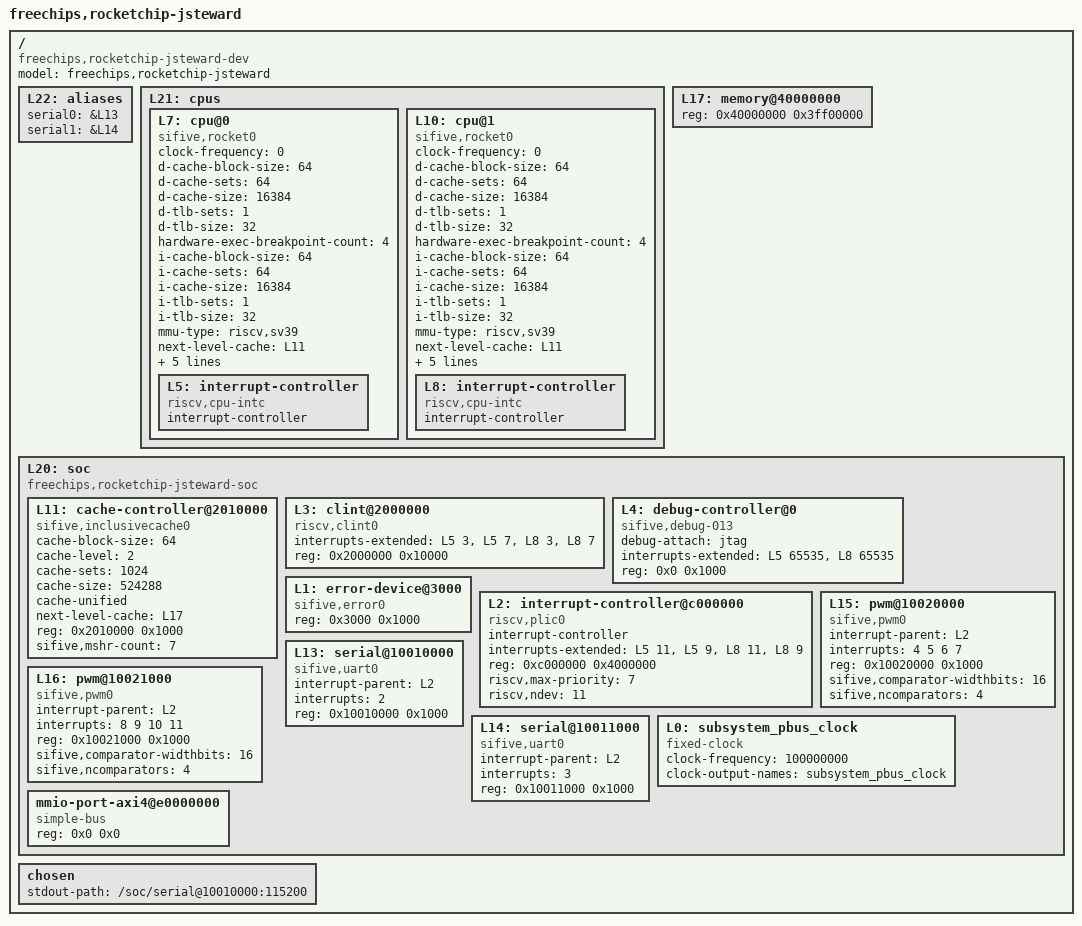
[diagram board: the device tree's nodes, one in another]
/dts-v1/;

/ {
	#address-cells = <1>;
	#size-cells = <1>;
	compatible = "freechips,rocketchip-jsteward-dev";
	model = "freechips,rocketchip-jsteward";
	L22: aliases {
		serial0 = &L13;
		serial1 = &L14;
	};
	L21: cpus {
		#address-cells = <1>;
		#size-cells = <0>;
		L7: cpu@0 {
			clock-frequency = <0>;
			compatible = "sifive,rocket0", "riscv";
			d-cache-block-size = <64>;
			d-cache-sets = <64>;
			d-cache-size = <16384>;
			d-tlb-sets = <1>;
			d-tlb-size = <32>;
			device_type = "cpu";
			hardware-exec-breakpoint-count = <4>;
			i-cache-block-size = <64>;
			i-cache-sets = <64>;
			i-cache-size = <16384>;
			i-tlb-sets = <1>;
			i-tlb-size = <32>;
			mmu-type = "riscv,sv39";
			next-level-cache = <&L11>;
			reg = <0x0>;
			riscv,isa = "rv64imafdc";
			riscv,pmpregions = <8>;
			status = "okay";
			timebase-frequency = <100000000>;
			tlb-split;
			L5: interrupt-controller {
				#interrupt-cells = <1>;
				compatible = "riscv,cpu-intc";
				interrupt-controller;
			};
		};
		L10: cpu@1 {
			clock-frequency = <0>;
			compatible = "sifive,rocket0", "riscv";
			d-cache-block-size = <64>;
			d-cache-sets = <64>;
			d-cache-size = <16384>;
			d-tlb-sets = <1>;
			d-tlb-size = <32>;
			device_type = "cpu";
			hardware-exec-breakpoint-count = <4>;
			i-cache-block-size = <64>;
			i-cache-sets = <64>;
			i-cache-size = <16384>;
			i-tlb-sets = <1>;
			i-tlb-size = <32>;
			mmu-type = "riscv,sv39";
			next-level-cache = <&L11>;
			reg = <0x1>;
			riscv,isa = "rv64imafdc";
			riscv,pmpregions = <8>;
			status = "okay";
			timebase-frequency = <100000000>;
			tlb-split;
			L8: interrupt-controller {
				#interrupt-cells = <1>;
				compatible = "riscv,cpu-intc";
				interrupt-controller;
			};
		};
	};
	L17: memory@40000000 {
		device_type = "memory";
		reg = <0x40000000 0x3ff00000>;
	};
	L20: soc {
		#address-cells = <1>;
		#size-cells = <1>;
		compatible = "freechips,rocketchip-jsteward-soc", "simple-bus";
		ranges;
		L11: cache-controller@2010000 {
			cache-block-size = <64>;
			cache-level = <2>;
			cache-sets = <1024>;
			cache-size = <524288>;
			cache-unified;
			compatible = "sifive,inclusivecache0", "cache";
			next-level-cache = <&L17>;
			reg = <0x2010000 0x1000>;
			reg-names = "control";
			sifive,mshr-count = <7>;
		};
		L3: clint@2000000 {
			compatible = "riscv,clint0";
			interrupts-extended = <&L5 3 &L5 7 &L8 3 &L8 7>;
			reg = <0x2000000 0x10000>;
			reg-names = "control";
		};
		L4: debug-controller@0 {
			compatible = "sifive,debug-013", "riscv,debug-013";
			debug-attach = "jtag";
			interrupts-extended = <&L5 65535 &L8 65535>;
			reg = <0x0 0x1000>;
			reg-names = "control";
		};
		L1: error-device@3000 {
			compatible = "sifive,error0";
			reg = <0x3000 0x1000>;
		};
		L2: interrupt-controller@c000000 {
			#interrupt-cells = <1>;
			compatible = "riscv,plic0";
			interrupt-controller;
			interrupts-extended = <&L5 11 &L5 9 &L8 11 &L8 9>;
			reg = <0xc000000 0x4000000>;
			reg-names = "control";
			riscv,max-priority = <7>;
			riscv,ndev = <11>;
		};
		L15: pwm@10020000 {
			compatible = "sifive,pwm0";
			interrupt-parent = <&L2>;
			interrupts = <4 5 6 7>;
			reg = <0x10020000 0x1000>;
			reg-names = "control";
			sifive,comparator-widthbits = <16>;
			sifive,ncomparators = <4>;
		};
		L16: pwm@10021000 {
			compatible = "sifive,pwm0";
			interrupt-parent = <&L2>;
			interrupts = <8 9 10 11>;
			reg = <0x10021000 0x1000>;
			reg-names = "control";
			sifive,comparator-widthbits = <16>;
			sifive,ncomparators = <4>;
		};
		L13: serial@10010000 {
			compatible = "sifive,uart0";
			interrupt-parent = <&L2>;
			interrupts = <2>;
			reg = <0x10010000 0x1000>;
			reg-names = "control";
		};
		L14: serial@10011000 {
			compatible = "sifive,uart0";
			interrupt-parent = <&L2>;
			interrupts = <3>;
			reg = <0x10011000 0x1000>;
			reg-names = "control";
		};
		L0: subsystem_pbus_clock {
			#clock-cells = <0>;
			clock-frequency = <100000000>;
			clock-output-names = "subsystem_pbus_clock";
			compatible = "fixed-clock";
        };
        mmio-port-axi4@e0000000 {
            #address-cells = <1>;
            #size-cells = <1>;
            compatible = "simple-bus";
            reg = <0x0 0x0>;
        };
    };
    chosen {
        stdout-path = "/soc/serial@10010000:115200";
    };
};
